# M481_v1 register map
File version: 1.0
Registers are 32-bit, read-write, reset 0x0 unless marked. A register's access mark holds for its fields unless they carry their own. Offsets are from the block's base; [hi:lo] are bit positions; {n}, {i} and the like mark numbered series.

## SPIM — SPIM Register Map
Base 0x40007000
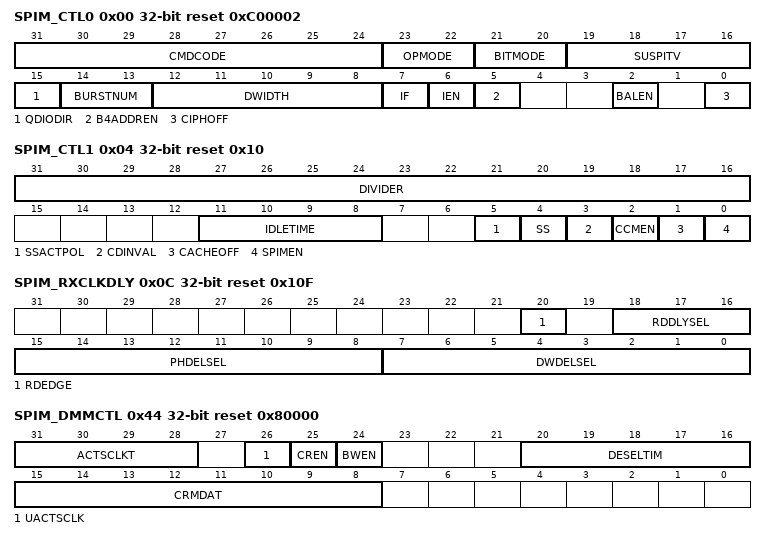
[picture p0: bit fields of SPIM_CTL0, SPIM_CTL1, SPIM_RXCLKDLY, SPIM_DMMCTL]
0x00 SPIM_CTL0 reset 0xC00002 — Control and Status Register 0
  [31:24] CMDCODE — Page Program Command Code (Note4). The Others command codes are Reserved. The DTR/DDR read commands '0x0D,0xBD,0xED' improves throughput by transferring address and data on both the falling and rising edge of SPI Flash clock (SPIM_CLK). It is similar to those commands '0x0B, 0xBB, 0xEB' but allows transfer of address and data on rising edge and falling edge of SPI Flash output clock. (Note2). Note1: Quad mode of SPI Flash must be enabled first by normal I/O mode before using quad page program/quad read commands. Note2: See SPI Flash specifications for support items. Note3: For TYPE_1, TYPE_2, and TYPE_3 of page program command code, refer to Figure 6.223, Figure 6.224, and Figure 6.225. Note4: Please disable 'continuous read mode' and 'burst wrap mode' before DMA write mode of SPI Flash controller is used to program data of external SPI Flash. After using DMA write mode of SPI Flash controller to program the content of external SPI Flash, please set CDINVAL(SPIM_CTL1[3]) to 0x1 (Set all cache data to be invalid).
    2=Page program (Used for DMA Write mode); 3=Standard Read (Used for DMA Read/DMM mode); 11=Fast Read (Used for DMA Read/DMM mode); 13=DTR/DDR Fast read (Used for DMA Read/DMM mode); 50=Quad page program with TYPE_1 program flow (Used for DMA Write mode). (Note3); 56=Quad page program with TYPE_2 program flow (Used for DMA Write mode). (Note3); 59=Fast Read Dual Output (Used for DMA Read/DMM mode); 64=Quad page program with TYPE_3 program flow (Used for DMA Write mode). (Note3); 187=Fast Read Dual I/O (Used for DMA Read/DMM mode); 189=DTR/DDR dual read (Used for DMA Read/DMM mode); 231=Word quad read (Used for DMA Read/DMM mode); 235=Fast quad read (Used for DMA Read/DMM mode); 237=DTR/DDR quad read (Used for DMA Read/DMM mode)
  [23:22] OPMODE — SPI Function Operation Mode. Note1: After using Normal I/O mode of SPI Flash controller to program the content of external SPI Flash, please set CDINVAL(SPIM_CTL1[3]) to 0x1 (Set all cache data to be invalid). Note2: In DMA write mode, hardware will send just one page program command per operation. Users must take care of cross-page cases. After using DMA write mode of SPI Flash controller to program the content of external SPI Flash, please set CDINVAL(SPIM_CTL1[3]) to 0x1 (Set all cache data to be invalid). Note3: For external SPI Flash with 32 Mbytes, access address range of external SPI Flash address is from 0x00000000 to 0x01FFFFFF when using Normal I/O mode, DMA write mode, and DMA read mode to write/read external SPI Flash data. Please user check size of used SPI Flash component to know access address range of external SPI Flash. Note4: For external SPI Flash with 32 Mbytes, access address range of external SPI Flash address is from 0x08000000 to 0x09FFFFFF when using Direct Memory mapping mode (DMM mode) to read external SPI Flash data. Please user check size of used SPI Flash component to know access address range of external SPI Flash.
    0=Normal I/O mode. (Note1) (Note3); 1=DMA write mode. (Note2) (Note3); 2=DMA read mode. (Note3); 3=Direct Memory Mapping mode (DMM mode) (Default). (Note4)
  [21:20] BITMODE — SPI Interface Bit Mode. Note: Only used for normal I/O mode.
    0=Standard mode; 1=Dual mode; 2=Quad mode
  [19:16] SUSPITV — Suspend Interval. Note: Only used for normal I/O mode.
    0=2 AHB clock cycles; 1=3 AHB clock cycles; 14=16 AHB clock cycles; 15=17 AHB clock cycles
  [15] QDIODIR — SPI Interface Direction Select for Quad/Dual Mode. Note: Only used for normal I/O mode.
    0=Interface signals are input; 1=Interface signals are output
  [14:13] BURSTNUM — Transmit/Receive Burst Number. This field specifies how many transmit/receive transactions should be executed continuously in one transfer. Note: Only used for normal I/O Mode.
    0=Only one transmit/receive transaction will be executed in one transfer; 1=Two successive transmit/receive transactions will be executed in one transfer; 2=Three successive transmit/receive transactions will be executed in one transfer; 3=Four successive transmit/receive transactions will be executed in one transfer
  [12:8] DWIDTH — Transmit/Receive Bit Length. This specifies how many bits are transmitted/received in one transmit/receive transaction. Note1: Only used for normal I/O mode. Note2: Only 8, 16, 24, and 32 bits are allowed. Other bit length will result in incorrect transfer.
    7=8 bits; 15=16 bits; 23=24 bits; 31=32 bits
  [7] IF — Interrupt Flag. Write Operation:
    0=No effect. The transfer has not finished yet; 1=Write 1 to clear. The transfer has done
  [6] IEN — Interrupt Enable Bit
    0=SPIM Interrupt Disabled; 1=SPIM Interrupt Enabled
  [5] B4ADDREN — 4-byte Address Mode Enable Bit. Note: Used for DMA write mode, DMA read mode, and DMM mode.
    0=4-byte address mode Disabled, and 3-byte address mode Enabled; 1=4-byte address mode Enabled
  [2] BALEN — Balance the AHB Control Time Between Cipher Enable and Disable Control. When cipher is enabled, the AHB control signal will delay some time caused by the encoding or decoding calculation. Therefore, if set BALEN to 1, it will make the AHB signal processing time with cipher disabled be equal to that with cipher enabled. Note: Only useful when cipher is disabled.
  [0] CIPHOFF — Cipher Disable Bit
    0=Cipher function Enabled; 1=Cipher function Disabled
0x04 SPIM_CTL1 reset 0x10 — Control Register 1
  [31:16] DIVIDER — Clock Divider Register. The value in this field is the frequency divider of the AHB clock (HCLK) to generate the serial SPI output clock 'SCLK' on the output SPIM_CLK pin. The desired frequency is obtained according to the following equation: . Note1: When set DIVIDER to zero, the frequency of SPIM_CLK will be equal to the frequency of HCLK. Note2: SCLK is serial SPI output clock. Note3: Please check the specification of the used SPI Flash component to decide the frequency of SPI Flash clock. Note4: For DTR/DDR read commands '0x0D, 0xBD, 0xED', the setting values of DIVIDER are only all multiples of 2. For example, 1,2,4,8,16,32,...
  [11:8] IDLETIME — Idle Time Interval. In DMM mode, IDLETIME is set to control the minimum idle time between two SPI Flash accesses.
  [5] SSACTPOL — Slave Select Active Level. It defines the active level of device/slave select signal (SPIM_SS), as shown in Table 6.222.
    0=The SPIM_SS slave select signal is active low; 1=The SPIM_SS slave select signal is active high
  [4] SS — Slave Select Active Enable Bit. Note: This interface can only drive one device/slave at a given time. Therefore, the slave selects of the selected device must be set to its active level before starting any read or write transfer. Functional description of SSACTPOL(SPIM_CTL1[5]) and SS is shown in Table 6.222.
    0=SPIM_SS is in active level; 1=SPIM_SS is in inactive level (Default)
  [3] CDINVAL — Cache Data Invalid Enable Bit. Write Operation: Read Operation: No effect. Note: When SPI Flash memory is page erasing or whole Flash erasing, please set CDINVAL to 0x1. After using normal I/O mode or DMA write mode of SPI Flash controller to program or erase the content of external SPI Flash, please set CDINVAL to 0x1.
    0=No effect; 1=Set all cache data to be invalid. This bit is cleared by hardware automatically
  [2] CCMEN — CCM (Core Coupled Memory) Mode Enable Bit. Note1: When CCM mode is enabled, the cache function will be disable by hardware automatically. When CCM mode is disabled, the cache function can be enabled or disabled by user. Note2: When CCM mode is disabled, user accesses the core coupled memory by bus master. In this case, the SPI Flash controller will send error response via HRESP bus signal to bus master. Note3: When CCM mode needs to be enabled, user sets CCMEN to 1 and needs to read this register to show the current hardware status. When reading data of CCMEN is 1, MCU can start to read data from CCM memory space or write data to CCM memory space.
    0=CCM mode Disabled. (Default); 1=CCM mode Enabled
  [1] CACHEOFF — Cache Memory Function Disable Bit. Note: When CCM mode is enabled, the cache function will be disable by hardware automatically. When CCM mode is disabled, the cache function can be enable or disable by user.
    0=Cache memory function Enabled. (Default); 1=Cache memory function Disabled
  [0] SPIMEN — Go and Busy Status. Write Operation: Note: All registers should be set before writing 1 to the SPIMEN bit. When a transfer is in progress, user should not write to any register of this peripheral.
    0=No effect. The transfer has done; 1=Start the transfer. This bit remains set during the transfer and is automatically cleared after transfer finished. The transfer has not finished yet
0x0C SPIM_RXCLKDLY reset 0x10F — RX Clock Delay Control Register
  [20] RDEDGE — Sampling Clock Edge Selection for Received Data (for Normal I/O Mode, DMA Read Mode, DMA Write Mode, and Direct Memory Mapping Mode)
    0=Use SPI input clock rising edge to sample received data. (Default); 1=Use SPI input clock falling edge to sample received data
  [18:16] RDDLYSEL — Sampling Clock Delay Selection for Received Data (for Normal I/O Mode, DMA Rread Mode, DMA Write Mode, and Direct Memory Mapping Mode). Determine the number of inserted delay cycles. Used to adjust the sampling clock of received data to latch the correct data. 0x0: No delay. (Default). 0x1: Delay 1 SPI Flash clock. 0x2: Delay 2 SPI Flash clocks. 0x3: Delay 3 SPI Flash clocks. ... 0x7: Delay 7 SPI Flash clocks. Note: The manufacturer or device ID of external SPI Flash component can be used to determine the correct setting value of RDDLYSEL. An example is given as follows. For example, the manufacturer ID and device ID of external SPI Flash for some vendor are 0xEF and 0x1234 separately. First, set RDDLYSEL to 0x0, and use read manufacturer id/device id command to read the manufacturer id of external SPI Flash by using normal I/O mode (the manufacturer id is 0xEF (1110_1111) in this example). If the manufacturer ID which reads from external SPI Flash is 0xF7 (1111_0111), it denotes that manufacturer id is shifted the right by 1 bit and most significant bit (MSB) of manufacturer id is assigned to 1. According to manufacturer id reads from external SPI Flash, RDDLYSEL needs to be set to 0x1 to receive SPI Flash data correctly.
  [15:8] PHDELSEL — SPI Flash Phase Delay Time (for DMA Write Mode, DMA Read Mode). The bits set phase delay time between command data phase, address data phase, and dummy cycle phase, where SPI Flash controller will send those phase data to external SPI Flash.
  [7:0] DWDELSEL — SPI Flash Deselect Time Interval of DMA Write Mode (for DMA Write Mode Only). The bits set the deselect time interval of SPI Flash (i.e. time interval of inactive level of SPIM_SS) when SPI Flash controller operates on DMA write mode. (Note1)
{0x10+4i} SPIM_RX{i} ro (i=0..3) — Data Receive Register {i}
  [31:0] RXDAT — Data Receive Register. The Data Receive Registers hold the received data of the last executed transfer. Number of valid RX registers is specified in SPIM_CTL0[BURSTNUM]. If BURSTNUM 0, received data are held in the most significant RXDAT register first. Number of valid-bit is specified in SPIM_CTL0[DWIDTH]. If DWIDTH is 16, 24, or 32, received data are held in the least significant byte of RXDAT register first. In a byte, received data are held in the most significant bit of RXDAT register first.
{0x20+4i} SPIM_TX{i} (i=0..3) — Data Transmit Register {i}
  [31:0] TXDAT — Data Transmit Register. The Data Transmit Registers hold the data to be transmitted in next transfer. Number of valid TXDAT registers is specified in SPIM_CTL0[BURSTNUM]. If BURSTNUM 0, data are transmitted in the most significant TXDAT register first. Number of valid-bit is specified in SPIM_CTL0[DWIDTH]. If DWIDTH is 16, 24, or 32, data are transmitted in the least significant byte of TXDAT register first. In a byte, data are transmitted in the most significant bit of TXDAT register first.
0x30 SPIM_SRAMADDR — SRAM Memory Address Register
  [31:0] ADDR — SRAM Memory Address. For DMA Read mode, this is the destination address for DMA transfer. For DMA Write mode, this is the source address for DMA transfer. Note: This address must be word-aligned.
0x34 SPIM_DMACNT — DMA Transfer Byte Count Register
  [23:0] DMACNT — DMA Transfer Byte Count Register. It indicates the transfer length for DMA process. Note1: The unit for counting is byte. Note2: The number must be the multiple of 4. Note3: Please check specification of used SPI Flash to know maximum byte length of page program.
0x38 SPIM_FADDR — SPI Flash Address Register
  [31:0] ADDR — SPI Flash Address Register. For DMA Read mode, this is the source address for DMA transfer. For DMA Write mode, this is the destination address for DMA transfer. Note1: This address must be word-aligned. Note2: For external SPI Flash with 32 Mbytes, the value of this SPI Flash address register 'ADDR' is from 0x00000000 to 0x01FFFFFF when using DMA write mode and DMA read mode to write/read external SPI Flash data. Please user check size of used SPI Flash component to know access address range of external SPI Flash.
0x3C SPIM_KEY1 wo — Cipher Key1 Register
  [31:0] KEY1 — Cipher Key1 Register. This is the KEY1 data for cipher function. Note1: If there is not any KEY1(SPIM_KEY1[31:0]) or KEY2(SPIM_KEY2[31:0]) (KEY1 is 0x0000_0000 or KEY2 is 0x0000_0000), the cipher function will be disabled automatically. Note2: When CIPHOFF(SPIM_CTL0[0]) is 0, both of KEY1(SPIM_KEY1[31:0]) and KEY2(SPIM_KEY2[31:0]) do not equal to 0x0000_0000 (i.e. KEY1 0x0000_0000 and KEY20x0000_0000), cipher encryption/decryption is enabled.
0x40 SPIM_KEY2 wo — Cipher Key2 Register
  [31:0] KEY2 — Cipher Key2 Register. This is the KEY2 data for cipher function. Note1: If there is not any KEY1(SPIM_KEY1[31:0]) or KEY2(SPIM_KEY2[31:0]) (KEY1 is 0x0000_0000 or KEY2 is 0x0000_0000), the cipher function will be disabled automatically. Note2: When CIPHOFF(SPIM_CTL0[0]) is 0, both of KEY1(SPIM_KEY1[31:0]) and KEY2(SPIM_KEY2[31:0]) do not equal to 0x0000_0000 (i.e. KEY1 0x0000_0000 and KEY20x0000_0000), cipher encryption/decryption is enabled.
0x44 SPIM_DMMCTL reset 0x80000 — Direct Memory Mapping Mode Control Register
  [31:28] ACTSCLKT — SPI Flash Active SCLK Time (Only for Direct Memory Mapping Mode, DMA Write Mode, and DMA Read Mode). The bits set time interval between SPIM SS active edge and the position edge of the first serial SPI output clock, as shown in Figure 6.2211.. Note2: SCLK is SPI output clock. Note3: Please check the used SPI Flash specification to know the setting value of this register, and different SPI Flash vendor may use different setting values.
  [26] UACTSCLK — User Sets SPI Flash Active SCLK Time (Only for Direct Memory Mapping Mode, DMA Write Mode, and DMA Read Mode). Note: When user wants to set ACTSCLKT(SPIM_DMMCTL[31:28]) manually, please set UACTSCLK to 1.
    0=According to DIVIDER(SPIM_CTL1[31:16]), ACTSCLKT(SPIM_DMMCTL[31:28]) is set by hardware automatically. (Default); 1=Set ACTSCLKT(SPIM_DMMCTL[31:28]) by user manually
  [25] CREN — Continuous Read Mode Enable Bit (Only for Direct Memory Mapping Mode, Read Command Codes 0xBB, 0xEB, 0xE7, 0x0D, 0xBD, 0xED). For read operations of SPI Flash, commands of fast read quad I/O (0xEB), word read quad I/O (0xE7), fast read dual I/O (0xBB), DTR/DDR fast read (0x0D), DTR/DDR fast read dual I/O (0xBD), and DTR/DDR fast read quad I/O (0xED) can further reduce command overhead through setting the 'continuous read mode' bits (8 bits) after the input address data. Note: When using function of continuous read mode and setting USETEN (SPIM_CTL2[16]) to 1, CRMDAT(SPIM_DMMCTL[15:8]) must be set by used SPI Flash specifications. When using function of continuous read mode and setting USETEN(SPIM_CTL2[16]) to 0, CRMDAT(SPIM_DMMCTL[15:8]) is set to value 0x20.
    0=Continuous Read Mode Disabled. (Default); 1=Continuous Read Mode Enabled
  [24] BWEN — 16 Bytes Burst Wrap Mode Enable Bit (Only for Direct Memory Mapping Mode, Cache Enable, and Read Command Code '0xEB, and 0xE7'). In direct memory mapping mode, both of quad read commands '0xEB' and '0xE7' support burst wrap mode for cache application and performance enhance. For cache application, the burst wrap mode can be used to fill the cache line quickly (In this SPI Flash controller, use cache data line with 16 bytes size). For performance enhance with direct memory mapping mode and cache enable, when cache data is miss, the burst wrap mode can let MCU get the required SPI Flash data quickly.
    0=Burst Wrap Mode Disabled. (Default); 1=Burst Wrap Mode Enabled
  [20:16] DESELTIM — SPI Flash Deselect Time (Only for Direct Memory Mapping Mode). Set the minimum time width of SPI Flash deselect time (i.e. Minimum SPIM_SS deselect time), as shown in Figure 6.2211. (1) Cache function disable: Note3: Please check the used SPI Flash specification to know the setting value of this register, and different SPI Flash vendor may use different setting values.
  [15:8] CRMDAT — Mode Bits Data for Continuous Read Mode (or Performance Enhance Mode) (Only for Direct Memory Mapping Mode). Set the mode bits data for continuous read mode (or performance enhance mode). When setting this mode bits currently (Note1) and set CREN(SPIM_DMMCTL[25]), this reduces the command phase by eight clocks and allows the read address to be immediately entered after SPIM_SS asserted to active. (Note1). Note1: Please check the used SPI Flash specification to know the setting value of this mode bits data, and different SPI Flash vendor may use different setting values. Note2: CRMDAT needs to be used with CREN(SPIM_DMMCTL[25]).
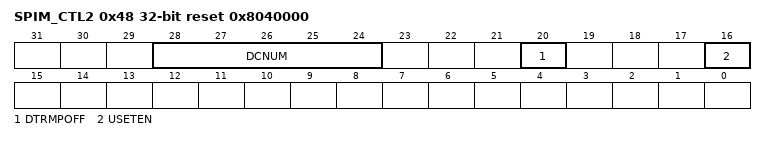
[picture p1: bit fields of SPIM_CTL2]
0x48 SPIM_CTL2 reset 0x8040000 — Control Register 2
  [28:24] DCNUM — Dummy Cycle Number (Only for Direct Memory Mapping Mode and DMA Read Mode). Set number of dummy cycles (1) For non-DTR/non-DDR command codes 0x03, 0x0B, 0x3B, 0xBB, 0xEB, and 0xE7: For command codes 0x0B, 0x3B, 0xEB, and 0xE7, user only set DCNUM to dummy cycle number by used SPI Flash specification. (2) For DTR/DDR command codes 0x0D, 0xBD, and 0xED: user sets DCNUM to dummy cycle number and DTRMPOFF(SPIM_CTL2[20]) by used SPI Flash specification. Note: Number of dummy cycles depends on the frequency of SPI output clock, SPI Flash vendor, and read command types. Please check the used SPI Flash specification to know the setting value of this number of dummy cycles.
  [20] DTRMPOFF — Mode Phase OFF for DTR/DDR Command Codes 0x0D, 0xBD, and 0xED (Only for Direct Memory Mapping Mode and DMA Read Mode). Note: Please check the used SPI Flash specification to know the mode cycle number (or performance enhance cycle number) for DTR/DDR command codes 0x0D, 0xBD, and 0xED.
    0=Mode cycle number (or performance enhance cycle number) does not equal to 0x0 in DTR/DDR read command codes 0x0D, 0xBD, and 0xED; 1=mode cycle number (or performance enhance cycle number) equals to 0x0 in DTR/DDR read command codes 0x0D, 0xBD, and 0xED
  [16] USETEN — User Set Value Enable Bit (Only for Direct Memory Mapping Mode and DMA Read Mode with Read Commands 0x03,0x0B,0x3B,0xBB,0xEB,0xE7). For DTR/DDR command codes 0x0D, 0xBD, and 0xED, please set USETEN to 0x1.
    0=Hardware circuit of SPI Flash controller will use the following default values of DCNUM(SPIM_CTL2[28:24]) and CRMDAT(SPIM_DMMCTL[15:8]) to configure SPI Flash operations automatically; 1=If DCNUM(SPIM_CTL2[28:24]) and CRMDAT(SPIM_DMMCTL[15:8]) are not set as above default values, user must set USETEN to 0x1, DCNUM(SPIM_CTL2[28:24]) and CRMDAT(SPIM_DMMCTL[15:8]) to configure SPI Flash operations manually
